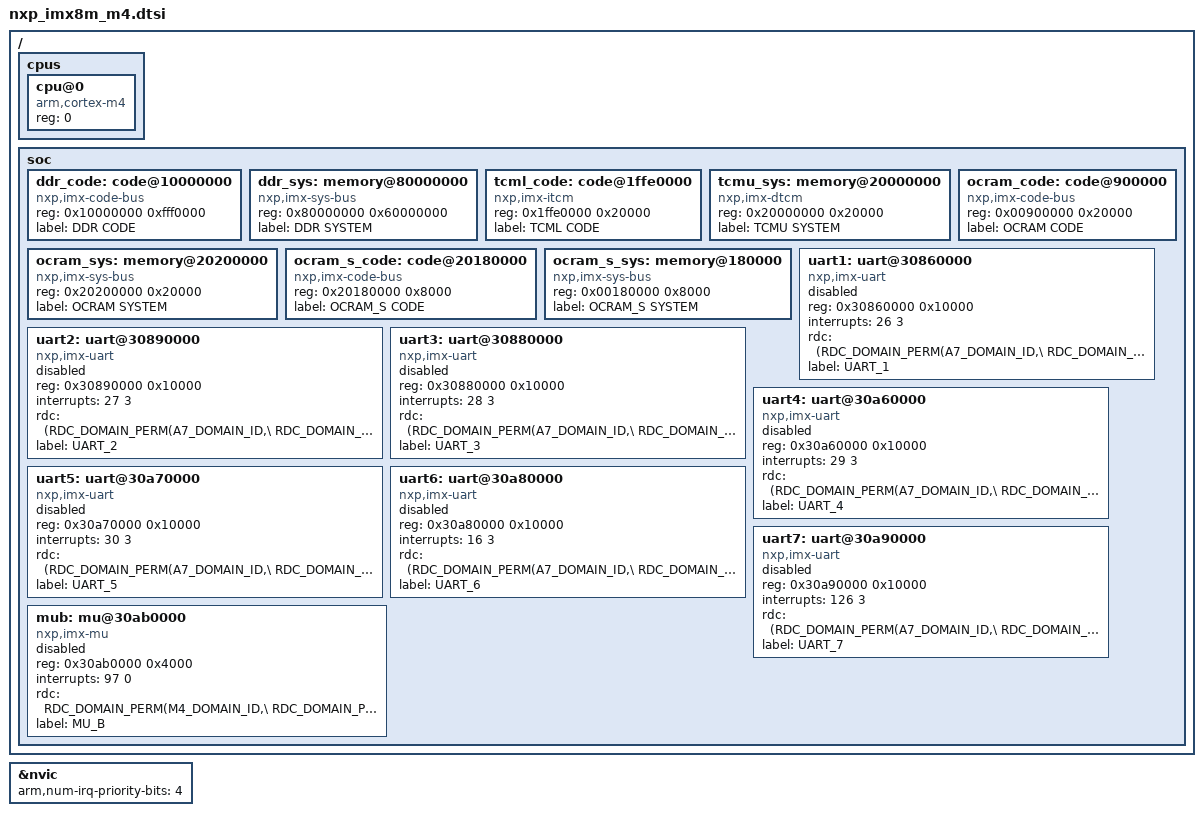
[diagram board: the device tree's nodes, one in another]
/*
 * Copyright (c) 2019, Prevas A/S
 *
 * SPDX-License-Identifier: Apache-2.0
 */

#include <arm/armv7-m.dtsi>
#include <dt-bindings/rdc/imx_rdc.h>

/ {
	cpus {
		#address-cells = <1>;
		#size-cells = <0>;

		cpu@0 {
			device_type = "cpu";
			compatible = "arm,cortex-m4";
			reg = <0>;
		};
	};

	soc {

		ddr_code: code@10000000 {
			compatible = "nxp,imx-code-bus";
			reg = <0x10000000 0xfff0000>;
			label = "DDR CODE";
		};

		ddr_sys: memory@80000000 {
			device_type = "memory";
			compatible = "nxp,imx-sys-bus";
			reg = <0x80000000 0x60000000>;
			label = "DDR SYSTEM";
		};

		tcml_code: code@1ffe0000 {
			compatible = "nxp,imx-itcm";
			reg = <0x1ffe0000 0x20000>;
			label = "TCML CODE";
		};

		tcmu_sys: memory@20000000 {
			compatible = "nxp,imx-dtcm";
			reg = <0x20000000 0x20000>;
			label = "TCMU SYSTEM";
		};

		ocram_code: code@900000 {
			compatible = "nxp,imx-code-bus";
			reg = <0x00900000 0x20000>;
			label = "OCRAM CODE";
		};

		ocram_sys: memory@20200000 {
			device_type = "memory";
			compatible = "nxp,imx-sys-bus";
			reg = <0x20200000 0x20000>;
			label = "OCRAM SYSTEM";
		};

		ocram_s_code: code@20180000 {
			compatible = "nxp,imx-code-bus";
			reg = <0x20180000 0x8000>;
			label = "OCRAM_S CODE";
		};

		ocram_s_sys: memory@180000 {
			device_type = "memory";
			compatible = "nxp,imx-sys-bus";
			reg = <0x00180000 0x8000>;
			label = "OCRAM_S SYSTEM";
		};

		uart1: uart@30860000 {
			compatible = "nxp,imx-uart";
			reg = <0x30860000 0x10000>;
			interrupts = <26 3>;
			rdc = <(RDC_DOMAIN_PERM(A7_DOMAIN_ID,\
					       RDC_DOMAIN_PERM_RW)|\
			       RDC_DOMAIN_PERM(M4_DOMAIN_ID,\
					       RDC_DOMAIN_PERM_RW))>;
			label = "UART_1";
			status = "disabled";
		};

		uart2: uart@30890000 {
			compatible = "nxp,imx-uart";
			reg = <0x30890000 0x10000>;
			interrupts = <27 3>;
			rdc = <(RDC_DOMAIN_PERM(A7_DOMAIN_ID,\
					       RDC_DOMAIN_PERM_RW)|\
			       RDC_DOMAIN_PERM(M4_DOMAIN_ID,\
					       RDC_DOMAIN_PERM_RW))>;
			label = "UART_2";
			status = "disabled";
		};

		uart3: uart@30880000 {
			compatible = "nxp,imx-uart";
			reg = <0x30880000 0x10000>;
			interrupts = <28 3>;
			rdc = <(RDC_DOMAIN_PERM(A7_DOMAIN_ID,\
					       RDC_DOMAIN_PERM_RW)|\
			       RDC_DOMAIN_PERM(M4_DOMAIN_ID,\
					       RDC_DOMAIN_PERM_RW))>;
			label = "UART_3";
			status = "disabled";
		};

		uart4: uart@30a60000 {
			compatible = "nxp,imx-uart";
			reg = <0x30a60000 0x10000>;
			interrupts = <29 3>;
			rdc = <(RDC_DOMAIN_PERM(A7_DOMAIN_ID,\
					       RDC_DOMAIN_PERM_RW)|\
			       RDC_DOMAIN_PERM(M4_DOMAIN_ID,\
					       RDC_DOMAIN_PERM_RW))>;
			label = "UART_4";
			status = "disabled";
		};

		uart5: uart@30a70000 {
			compatible = "nxp,imx-uart";
			reg = <0x30a70000 0x10000>;
			interrupts = <30 3>;
			rdc = <(RDC_DOMAIN_PERM(A7_DOMAIN_ID,\
					       RDC_DOMAIN_PERM_RW)|\
			       RDC_DOMAIN_PERM(M4_DOMAIN_ID,\
					       RDC_DOMAIN_PERM_RW))>;
			label = "UART_5";
			status = "disabled";
		};

		uart6: uart@30a80000 {
			compatible = "nxp,imx-uart";
			reg = <0x30a80000 0x10000>;
			interrupts = <16 3>;
			rdc = <(RDC_DOMAIN_PERM(A7_DOMAIN_ID,\
					       RDC_DOMAIN_PERM_RW)|\
			       RDC_DOMAIN_PERM(M4_DOMAIN_ID,\
					       RDC_DOMAIN_PERM_RW))>;
			label = "UART_6";
			status = "disabled";
		};

		uart7: uart@30a90000 {
			compatible = "nxp,imx-uart";
			reg = <0x30a90000 0x10000>;
			interrupts = <126 3>;
			rdc = <(RDC_DOMAIN_PERM(A7_DOMAIN_ID,\
					       RDC_DOMAIN_PERM_RW)|\
			       RDC_DOMAIN_PERM(M4_DOMAIN_ID,\
					       RDC_DOMAIN_PERM_RW))>;
			label = "UART_7";
			status = "disabled";
		};

		mub:mu@30ab0000 {
			compatible = "nxp,imx-mu";
			reg = <0x30ab0000 0x4000>;
			interrupts = <97 0>;
			rdc = <RDC_DOMAIN_PERM(M4_DOMAIN_ID,\
					       RDC_DOMAIN_PERM_RW)>;
			label = "MU_B";
			status = "disabled";
		};

	};
};

&nvic {
	arm,num-irq-priority-bits = <4>;
};
